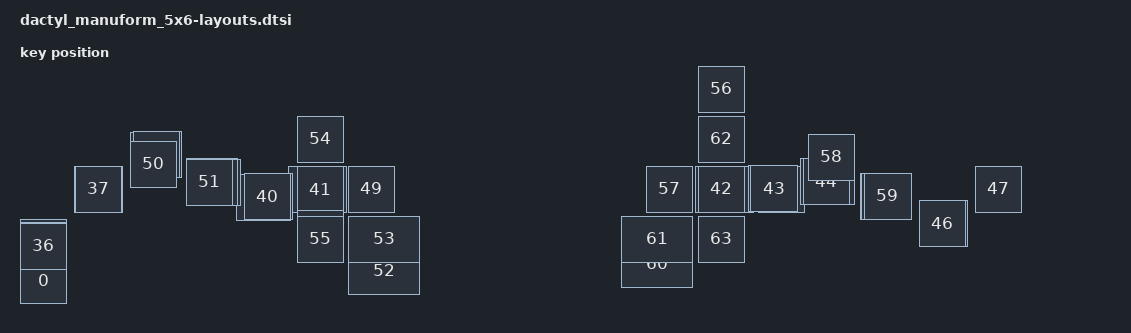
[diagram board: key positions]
// See https://zmk.dev/docs/development/hardware-integration/physical-layouts
// for how to configure this.

#include <physical_layouts.dtsi>

/ {
    physical_layout0: physical_layout_0 {
        compatible = "zmk,physical-layout";
        display-name = "Default Layout";
        transform = <&default_transform>;
        kscan = <&kscan0>;

        // Edit this to define the positions and sizes of the keys, or remove it
        // if your keyboard will not support ZMK Studio.
        // https://zmk.dev/docs/development/hardware-integration/physical-layouts#optional-keys-property
        keys  //                     w   h    x    y     rot    rx    ry
            = <&key_physical_attrs	100	100	1	383	0	0	0>
			, <&key_physical_attrs	100	100	108	200	0	0	0>
			, <&key_physical_attrs	100	100	220	132	0	0	0>
			, <&key_physical_attrs	100	100	333	185	0	0	0>
			, <&key_physical_attrs	100	100	433	216	0	0	0>
			, <&key_physical_attrs	100	100	536	200	0	0	0>
			, <&key_physical_attrs	100	100	1374	200	0	0	0>
			, <&key_physical_attrs	100	100	1477	200	0	0	0>
			, <&key_physical_attrs	100	100	1577	184	0	0	0>
			, <&key_physical_attrs	100	100	1690	215	0	0	0>
			, <&key_physical_attrs	100	100	1802	268	0	0	0>
			, <&key_physical_attrs	100	100	1910	200	0	0	0>
			, <&key_physical_attrs	100	100	0	306	0	0	0>
			, <&key_physical_attrs	100	100	111	200	0	0	0>
			, <&key_physical_attrs	100	100	227	131	0	0	0>
			, <&key_physical_attrs	100	100	344	185	0	0	0>
			, <&key_physical_attrs	100	100	448	217	0	0	0>
			, <&key_physical_attrs	100	100	554	200	0	0	0>
			, <&key_physical_attrs	100	100	1356	200	0	0	0>
			, <&key_physical_attrs	100	100	1462	199	0	0	0>
			, <&key_physical_attrs	100	100	1566	184	0	0	0>
			, <&key_physical_attrs	100	100	1683	215	0	0	0>
			, <&key_physical_attrs	100	100	1799	269	0	0	0>
			, <&key_physical_attrs	100	100	1910	200	0	0	0>
			, <&key_physical_attrs	100	100	0	313	0	0	0>
			, <&key_physical_attrs	100	100	113	200	0	0	0>
			, <&key_physical_attrs	100	100	230	131	0	0	0>
			, <&key_physical_attrs	100	100	348	186	0	0	0>
			, <&key_physical_attrs	100	100	453	215	0	0	0>
			, <&key_physical_attrs	100	100	560	201	0	0	0>
			, <&key_physical_attrs	100	100	1350	200	0	0	0>
			, <&key_physical_attrs	100	100	1457	199	0	0	0>
			, <&key_physical_attrs	100	100	1562	185	0	0	0>
			, <&key_physical_attrs	100	100	1680	214	0	0	0>
			, <&key_physical_attrs	100	100	1798	269	0	0	0>
			, <&key_physical_attrs	100	100	1910	200	0	0	0>
			, <&key_physical_attrs	100	100	0	314	0	0	0>
			, <&key_physical_attrs	100	100	111	200	0	0	0>
			, <&key_physical_attrs	100	100	227	131	0	0	0>
			, <&key_physical_attrs	100	100	344	186	0	0	0>
			, <&key_physical_attrs	100	100	448	215	0	0	0>
			, <&key_physical_attrs	100	100	554	201	0	0	0>
			, <&key_physical_attrs	100	100	1356	200	0	0	0>
			, <&key_physical_attrs	100	100	1462	199	0	0	0>
			, <&key_physical_attrs	100	100	1566	185	0	0	0>
			, <&key_physical_attrs	100	100	1683	214	0	0	0>
			, <&key_physical_attrs	100	100	1799	269	0	0	0>
			, <&key_physical_attrs	100	100	1910	200	0	0	0>
			, <&key_physical_attrs	100	100	554	288	0	0	0>
			, <&key_physical_attrs	100	100	657	200	0	0	0>
			, <&key_physical_attrs	100	100	220	150	0	0	0>
			, <&key_physical_attrs	100	100	333	186	0	0	0>
			, <&key_physical_attrs	150	100	657	364	0	0	0>
			, <&key_physical_attrs	150	100	657	300	0	0	0>
			, <&key_physical_attrs	100	100	554	100	0	0	0>
			, <&key_physical_attrs	100	100	554	300	0	0	0>
			, <&key_physical_attrs	100	100	1356	0	0	0	0>
			, <&key_physical_attrs	100	100	1253	200	0	0	0>
			, <&key_physical_attrs	100	100	1577	136	0	0	0>
			, <&key_physical_attrs	100	100	1690	214	0	0	0>
			, <&key_physical_attrs	150	100	1203	350	0	0	0>
			, <&key_physical_attrs	150	100	1203	300	0	0	0>
			, <&key_physical_attrs	100	100	1356	100	0	0	0>
			, <&key_physical_attrs	100	100	1356	300	0	0	0>
            ;
    };
};
